# cslr_dev register map
Vendor: Texas Instruments
Peripheral module from a debugger description file (folder TCI6484_C6457).
Registers are 32-bit, access not given, reset 0x0 unless marked. A register's access mark holds for its fields unless they carry their own. Offsets are as the file gives them; lines under a group give offsets from that group; [hi:lo] are bit positions; {n}, {i} and the like mark numbered series; 'fields as' and 'values as' point back to an identical list; <NAME> marks a mode.

## DEV — Device Registers on the SOC
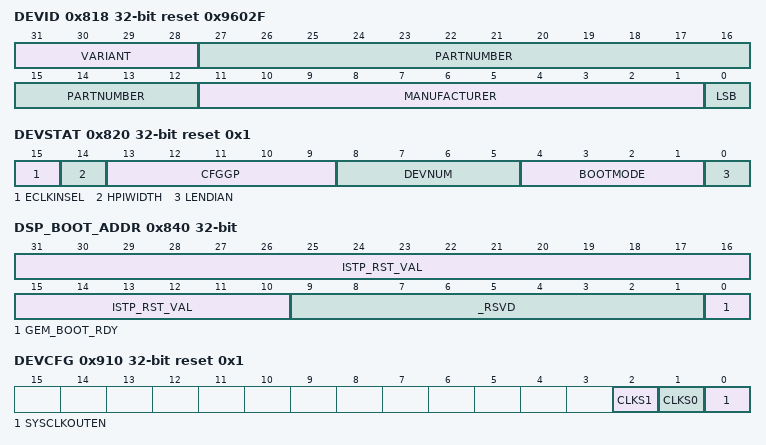
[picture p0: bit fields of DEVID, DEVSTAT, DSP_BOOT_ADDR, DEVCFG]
0x818 DEVID ro reset 0x9602F — Parameters for DSP device ID. Also referred to as JTAG or BSDL ID.These are readable by the configuration bus and can be accessed via the JTAG and the CPU.
  [31:28] VARIANT — Variant (4-Bit) value. The value of this field depends on the silicon revision being used.
  [27:12] PARTNUMBER — Part Number for boundary scan
  [11:1] MANUFACTURER
  [0] LSB — This bit is read as a 1 for TCI6484
0x820 DEVSTAT reset 0x1 — Device Status Register
  [15] ECLKINSEL ro — EMIFA input clock select
    0=ECLKIN; 1=SYSCLK7 (SYSCLK7 (CPU/x) Clock Rate. The SYSCLK7 clock rate is software selectable via the PLL1 Controller. By default, SYSCLK7 is selected as CPU/10 clock rate.)
  [14] HPIWIDTH ro — HPI bus width control bit
    0=16BIT (HPI operating in 16-bit mode); 1=32BIT (HPI operating in 32-bit mode)
  [13:9] CFGGP ro — Used as general purpose input for configuration purposes. These pins are latched at power-on reset. These values can be used by software routines for boot operations.
  [8:5] DEVNUM ro — Device number
  [4:1] BOOTMODE ro — Determines the boot method for the device.
  [0] LENDIAN ro — Device Endian Mode
    0=BE (System is operating in Big Endian Mode); 1=LE (System is operating in Little Endian Mode)
0x838 KICK0 rw — Key register 0
  [31:0] KICK0 — Two successive key writes are required to get write access to any of the device state control registers. KICK0 is the first key register. The written data must be 0x83E70B13 to unlock it and it must be written. before the KICK1 register. Writing any other value will lock the device state control registers.
0x83C KICK1 rw — Key register 1
  [31:0] KICK1 — KICK1 is the second key register to be unlocked in order to get write access to any of the device state control registers. The written data must be 0x95A4F1E0 to unlock it and it must be written after the KICK0 register. Writing any other value will lock the device state control registers.
0x840 DSP_BOOT_ADDR — DSP Boot Address
  [31:10] ISTP_RST_VAL rw — On Non-Secure device  This field is RW by any Master or Emulator. On Secure device  This field is Read-only by Secure Master. Emulator cannot access this in Secure mode.
  [9:1] _RSVD — (access N)
  [0] GEM_BOOT_RDY rw
0x910 DEVCFG reset 0x1 — Device Configuration Register
  [2] CLKS1 rw — McBSP1 CLKS Select
    0=CLKS1 (CLKS1 device pin); 1=CHIP_CLKS (chip_clks from Main.PLL)
  [1] CLKS0 rw — McBSP0 CLKS Select
    0=CLKS0 (CLKS0 device pin); 1=CHIP_CLKS (chip_clks from Main.PLL)
  [0] SYSCLKOUTEN rw — SYSCLKOUT Enable
    0=DISABLED (No Clock Output); 1=ENABLED (Clock output Enabled)
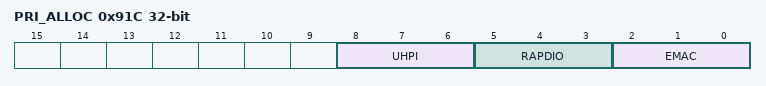
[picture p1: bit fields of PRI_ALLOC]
0x91C PRI_ALLOC (reset mask 0xFFFFFE00) — Priority Allocation Register
  [8:6] UHPI rw — VLYNQ priority
  [5:3] RAPDIO rw — RapidIO CPPI priority
  [2:0] EMAC rw — Emac Priority
0x920 WDRSTSEL — Reset select for Watchdog
  [0] WDRSTSEL rw — Reset select for watchdog timer
    0=DISABLED (TOUT1L does not cause WDRST to assert to GEM.); 1=ENABLED (TOUT1L causes a reset of the GEM via the host reset port of the LPSC)
